AUTOSAR XML (schema 00054)
package /SwComponentTypes
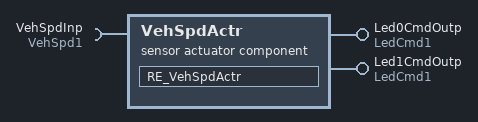
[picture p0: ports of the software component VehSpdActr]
  sensor actuator sw component type VehSpdActr: sensor-actuator=SensorActuatorType
    require port VehSpdInp: nonqueued-receiver-com-spec{data-element=VehSpd, init-value=Default_VehSpdInp:0}, required-interface=VehSpd1
    provide port Led0CmdOutp: provided-interface=LedCmd1
    provide port Led1CmdOutp: provided-interface=LedCmd1
    behavior VehSpdActr_IB: data-type-mapping=[DataTypeMappingSet_Spd, DataTypeMappingSet_LedOnOff], supports-multiple-instantiation=true
      data received event DRE_VehSpdInp: start-on-event=RE_VehSpdActr, data=VehSpdInp.VehSpd
      runnable RE_VehSpdActr: minimum-start-interval=0.01
        data-read-access:
          access DRA_VehSpdInp: accessed-variable=VehSpdInp.VehSpd
        data-write-access:
          access DWA_Led0CmdOutp: accessed-variable=Led0CmdOutp.Cmd
          access DWA_Led1CmdOutp: accessed-variable=Led1CmdOutp.Cmd
